# apollo3 register map
Vendor: Ambiq Micro; Series: Apollo; File version: 1.0
CPU: CM4 r1p0, little endian, MPU, FPU, 3 interrupt priority bits
Registers are 32-bit, read-write, reset 0x0 unless marked. A register's access mark holds for its fields unless they carry their own. Offsets are from the block's base; [hi:lo] are bit positions; lines under a group give offsets from that group; {n}, {i} and the like mark numbered series; 'fields as' and 'values as' point back to an identical list.

## GPIO — General Purpose IO
Base 0x40010000
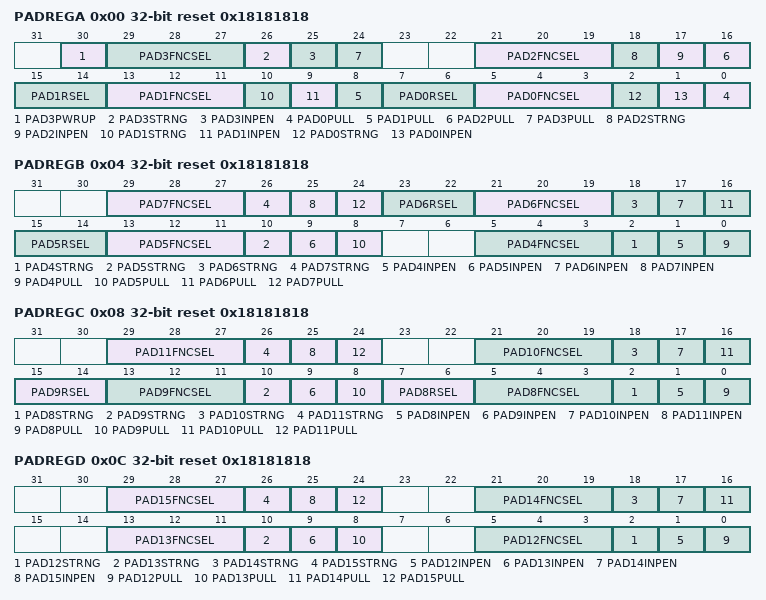
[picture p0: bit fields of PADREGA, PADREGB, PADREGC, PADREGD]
0x00 PADREGA reset 0x18181818 — Pad Configuration Register A (Pads 0-3)
  [30] PAD3PWRUP — Pad 3 VDD power switch enable
    0=DIS (Power switch disabled value.); 1=EN (Power switch enabled (switched to VDD) value.)
  [29:27] PAD3FNCSEL — Pad 3 function select
    0=UA0RTS (Configure as the UART0 RTS output value.); 1=SLnCE (Configure as the IOSLAVE SPI nCE signal value.); 2=NCE3 (IOM/MSPI nCE group 3 value.); 3=GPIO3 (Configure as GPIO3 value.); 5=MSPI7 (MSPI data connection 7 value.); 6=TRIG1 (Configure as the ADC Trigger 1 signal value.); 7=I2S_WCLK (Configure as the PDM I2S Word Clock input value.)
  [26] PAD3STRNG — Pad 3 drive strength.
    0=LOW (Low drive strength value.); 1=HIGH (High drive strength value.)
  [25] PAD3INPEN — Pad 3 input enable.
    0=DIS (Pad input disabled value.); 1=EN (Pad input enabled value.)
  [8n] PAD{n}PULL (n=0..3) — Pad {n} pullup enable
    0=DIS (Pullup disabled value.); 1=EN (Pullup enabled value.)
  [21:19] PAD2FNCSEL — Pad 2 function select
    1=SLMISO (Configure as the IOSLAVE SPI MISO signal value.); 2=UART0RX (Configure as the UART0 RX input value.); 3=GPIO2 (Configure as GPIO2 value.); 5=MSPI6 (CMSPI data connection 6 value.); 7=NCE2 (IOM/MSPI nCE group 2 value.)
  [18] PAD2STRNG — Pad 2 drive strength
    values as PAD3STRNG
  [17] PAD2INPEN — Pad 2 input enable
    values as PAD3INPEN
  [15:14] PAD1RSEL — Pad 1 pullup resistor selection.
    0=PULL1_5K (Pullup is ~1.5 KOhms value.); 1=PULL6K (Pullup is ~6 KOhms value.); 2=PULL12K (Pullup is ~12 KOhms value.); 3=PULL24K (Pullup is ~24 KOhms value.)
  [13:11] PAD1FNCSEL — Pad 1 function select
    0=SLSDAWIR3 (Configure as the IOSLAVE I2C SDA or SPI WIR3 signal value.); 1=SLMOSI (Configure as the IOSLAVE SPI MOSI signal value.); 2=UART0TX (Configure as the UART0 TX output signal value.); 3=GPIO1 (Configure as GPIO1 value.); 5=MSPI5 (MSPI data connection 5 value.); 7=NCE1 (IOM/MSPI nCE group 1 value.)
  [10] PAD1STRNG — Pad 1 drive strength
    values as PAD3STRNG
  [9] PAD1INPEN — Pad 1 input enable
    values as PAD3INPEN
  [7:6] PAD0RSEL — Pad 0 pullup resistor selection.
    values as PAD1RSEL
  [5:3] PAD0FNCSEL — Pad 0 function select
    0=SLSCL (Configure as the IOSLAVE I2C SCL signal value.); 1=SLSCK (Configure as the IOSLAVE SPI SCK signal value.); 2=CLKOUT (Configure as the CLKOUT signal value.); 3=GPIO0 (Configure as GPIO0 value.); 5=MSPI4 (MSPI data connection 4 value.); 7=NCE0 (IOM/MSPI nCE group 0 value.)
  [2] PAD0STRNG — Pad 0 drive strength
    values as PAD3STRNG
  [1] PAD0INPEN — Pad 0 input enable
    values as PAD3INPEN
0x04 PADREGB reset 0x18181818 — Pad Configuration Register B (Pads 4-7)
  [29:27] PAD7FNCSEL — Pad 7 function select
    0=NCE7 (IOM/MSPI nCE group 7 value.); 1=M0MOSI (Configure as the IOMSTR0 SPI MOSI signal value.); 2=CLKOUT (Configure as the CLKOUT signal value.); 3=GPIO7 (Configure as GPIO7 value.); 4=TRIG0 (Configure as the ADC Trigger 0 signal value.); 5=UART0TX (Configure as the UART0 TX output signal value.); 7=CT19 (CTIMER connection 19 value.)
  [8n-30] PAD{n}STRNG (n=4..7) — Pad {n} drive strength
    values as PADREGA.PAD3STRNG
  [8n-31] PAD{n}INPEN (n=4..7) — Pad {n} input enable
    values as PADREGA.PAD3INPEN
  [8n-32] PAD{n}PULL (n=4..7) — Pad {n} pullup enable
    0=DIS (Pullup disabled value.); 1=EN (Pullup enabled value.)
  [23:22] PAD6RSEL — Pad 6 pullup resistor selection.
    values as PADREGA.PAD1RSEL
  [21:19] PAD6FNCSEL — Pad 6 function select
    0=M0SDAWIR3 (Configure as the IOMSTR0 I2C SDA or SPI WIR3 signal value.); 1=M0MISO (Configure as the IOMSTR0 SPI MISO signal value.); 2=UA0CTS (Configure as the UART0 CTS input signal value.); 3=GPIO6 (Configure as GPIO6 value.); 5=CT10 (CTIMER connection 10 value.); 7=I2S_DAT (Configure as the PDM I2S Data output signal value.)
  [15:14] PAD5RSEL — Pad 5 pullup resistor selection.
    values as PADREGA.PAD1RSEL
  [13:11] PAD5FNCSEL — Pad 5 function select
    0=M0SCL (Configure as the IOMSTR0 I2C SCL signal value.); 1=M0SCK (Configure as the IOMSTR0 SPI SCK signal value.); 2=UA0RTS (Configure as the UART0 RTS signal output value.); 3=GPIO5 (Configure as GPIO5 value.); 5=EXTHFA (Configure as the External HFA input clock value.); 7=CT8 (CTIMER connection 8 value.)
  [5:3] PAD4FNCSEL — Pad 4 function select
    0=UA0CTS (Configure as the UART0 CTS input signal value.); 1=SLINT (Configure as the IOSLAVE interrupt out signal value.); 2=NCE4 (IOM/SPI nCE group 4 value.); 3=GPIO4 (Configure as GPIO4 value.); 5=UART0RX (Configure as the UART0 RX input value.); 6=CT17 (CTIMER connection 17 value.); 7=MSPI2 (MSPI data connection 2 value.)
0x08 PADREGC reset 0x18181818 — Pad Configuration Register C (Pads 8-11)
  [29:27] PAD11FNCSEL — Pad 11 function select
    0=ADCSE2 (Configure as the analog input for ADC single ended input 2 value.); 1=NCE11 (IOM/MSPI nCE group 11 value.); 2=CT31 (CTIMER connection 31 value.); 3=GPIO11 (Configure as GPIO11 value.); 4=SLINT (Configure as the IOSLAVE interrupt out signal value.); 5=UA1CTS (Configure as the UART1 CTS input signal value.); 6=UART0RX (Configure as the UART0 RX input signal value.); 7=PDM_DATA (Configure as the PDM Data input signal value.)
  [8n-62] PAD{n}STRNG (n=8..11) — Pad {n} drive strength
    values as PADREGA.PAD3STRNG
  [8n-63] PAD{n}INPEN (n=8..11) — Pad {n} input enable
    values as PADREGA.PAD3INPEN
  [8n-64] PAD{n}PULL (n=8..11) — Pad {n} pullup enable
    0=DIS (Pullup disabled value.); 1=EN (Pullup enabled value.)
  [21:19] PAD10FNCSEL — Pad 10 function select
    1=M1MOSI (Configure as the IOMSTR1 SPI MOSI signal value.); 2=NCE10 (IOM/MSPI nCE group 10 value.); 3=GPIO10 (Configure as GPIO10 value.); 4=PDMCLK (PDM serial clock out value.); 5=UA1RTS (Configure as the UART1 RTS output signal value.)
  [15:14] PAD9RSEL — Pad 9 pullup resistor selection
    values as PADREGA.PAD1RSEL
  [13:11] PAD9FNCSEL — Pad 9 function select
    0=M1SDAWIR3 (Configure as the IOMSTR1 I2C SDA or SPI WIR3 signal value.); 1=M1MISO (Configure as the IOMSTR1 SPI MISO signal value.); 2=NCE9 (IOM/MSPI nCE group 9 value.); 3=GPIO9 (Configure as GPIO9 value.); 4=SCCIO (SCARD data I/O connection value.); 6=UART1RX (Configure as UART1 RX input signal value.)
  [7:6] PAD8RSEL — Pad 8 pullup resistor selection.
    values as PADREGA.PAD1RSEL
  [5:3] PAD8FNCSEL — Pad 8 function select
    0=M1SCL (Configure as the IOMSTR1 I2C SCL signal value.); 1=M1SCK (Configure as the IOMSTR1 SPI SCK signal value.); 2=NCE8 (IOM/MSPI nCE group 8 value.); 3=GPIO8 (Configure as GPIO8 value.); 4=SCCLK (SCARD serial clock output value.); 6=UART1TX (Configure as the UART1 TX output signal value.)
0x0C PADREGD reset 0x18181818 — Pad Configuration Register D (Pads 12-15)
  [29:27] PAD15FNCSEL — Pad 15 function select
    0=ADCD1N (Configure as the analog ADC differential pair 1 N input signal value.); 1=NCE15 (IOM/MSPI nCE group 15 value.); 2=UART1RX (Configure as the UART1 RX signal value.); 3=GPIO15 (Configure as GPIO15 value.); 4=PDMDATA (PDM serial data input value.); 5=EXTXT (Configure as the external XTAL oscillator input value.); 6=SWDIO (Configure as an alternate port for the SWDIO I/O signal value.); 7=SWO (Configure as an SWO (Serial Wire Trace output) value.)
  [8n-94] PAD{n}STRNG (n=12..15) — Pad {n} drive strength
    values as PADREGA.PAD3STRNG
  [8n-95] PAD{n}INPEN (n=12..15) — Pad {n} input enable
    values as PADREGA.PAD3INPEN
  [8n-96] PAD{n}PULL (n=12..15) — Pad {n} pullup enable
    0=DIS (Pullup disabled value.); 1=EN (Pullup enabled value.)
  [21:19] PAD14FNCSEL — Pad 14 function select
    0=ADCD1P (Configure as the analog ADC differential pair 1 P input signal value.); 1=NCE14 (IOM/MSPI nCE group 14 value.); 2=UART1TX (Configure as the UART1 TX output signal value.); 3=GPIO14 (Configure as GPIO14 value.); 4=PDMCLK (PDM serial clock output value.); 5=EXTHFS (Configure as the External HFRC oscillator input select value.); 6=SWDCK (Configure as the alternate input for the SWDCK input signal value.); 7=32kHzXT (Configure as the 32kHz crystal output signal value.)
  [13:11] PAD13FNCSEL — Pad 13 function select
    0=ADCD0PSE8 (Configure as the ADC Differential pair 0 P, or Single Ended input 8 analog input signal. Determination of the D0P vs SE8 usage is done when the particular channel is selected within the ADC module value.); 1=NCE13 (IOM/MSPI nCE group 13 value.); 2=CT2 (CTIMER connection 2 value.); 3=GPIO13 (Configure as GPIO13 value.); 4=I2SBCLK (I2C interface bit clock value.); 5=EXTHFB (Configure as the external HFRC oscillator input value.); 6=UA0RTS (Configure as the UART0 RTS signal output value.); 7=UART1RX (Configure as the UART1 RX input signal value.)
  [5:3] PAD12FNCSEL — Pad 12 function select
    0=ADCD0NSE9 (Configure as the ADC Differential pair 0 N, or Single Ended input 9 analog input signal. Determination of the D0N vs SE9 usage is done when the particular channel is selected within the ADC module value.); 1=NCE12 (IOM/MSPI nCE group 12 value.); 2=CT0 (CTIMER connection 0 value.); 3=GPIO12 (Configure as GPIO12 value.); 4=SLnCE (Configure as the IOSLAVE SPI nCE signal value.); 5=PDMCLK (PDM serial clock output value.); 6=UA0CTS (Configure as the UART0 CTS input signal value.); 7=UART1TX (Configure as the UART1 TX output signal value.)
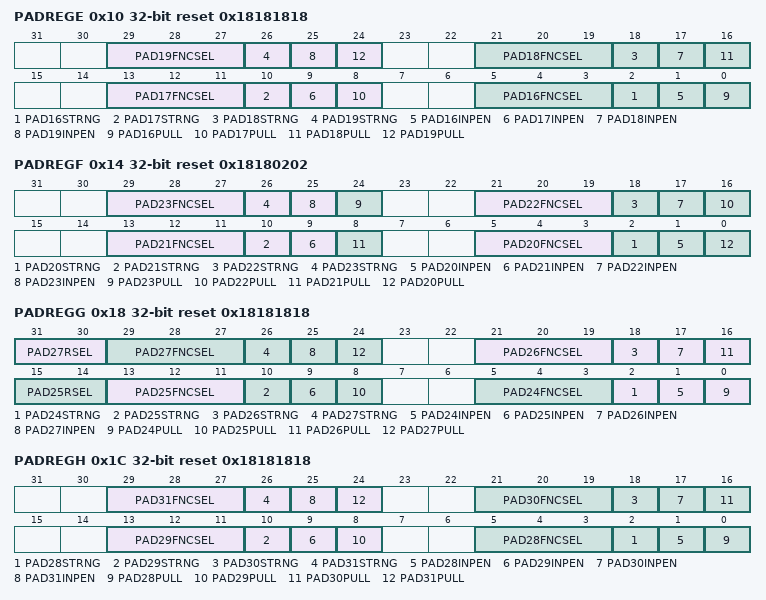
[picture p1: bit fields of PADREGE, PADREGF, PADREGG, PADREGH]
0x10 PADREGE reset 0x18181818 — Pad Configuration Register E (Pads 16-19)
  [29:27] PAD19FNCSEL — Pad 19 function select
    0=CMPRF0 (Configure as the analog comparator reference 0 signal value.); 1=NCE19 (IOM/MSPI nCE group 19 value.); 2=CT6 (CTIMER conenction 6 value.); 3=GPIO19 (Configure as GPIO19 value.); 4=SCCLK (SCARD serial clock value.); 5=ANATEST1 (Configure as the ANATEST1 I/O signal value.); 6=UART1RX (Configure as the UART1 RX input signal value.); 7=I2SBCLK (Configure as the PDM I2S bit clock input signal value.)
  [8n-126] PAD{n}STRNG (n=16..19) — Pad {n} drive strength
    values as PADREGA.PAD3STRNG
  [8n-127] PAD{n}INPEN (n=16..19) — Pad {n} input enable
    values as PADREGA.PAD3INPEN
  [8n-128] PAD{n}PULL (n=16..19) — Pad {n} pullup enable
    0=DIS (Pullup disabled value.); 1=EN (Pullup enabled value.)
  [21:19] PAD18FNCSEL — Pad 18 function select
    0=CMPIN1 (Configure as the analog comparator input 1 signal value.); 1=NCE18 (IOM/MSPI nCE group 18 value.); 2=CT4 (CTIMER connection 4 value.); 3=GPIO18 (Configure as GPIO18 value.); 4=UA0RTS (Configure as UART0 RTS output signal value.); 5=ANATEST2 (Configure as ANATEST2 I/O signal value.); 6=UART1TX (Configure as UART1 TX output signal value.); 7=SCCIO (SCARD data input/output connectin value.)
  [13:11] PAD17FNCSEL — Pad 17 function select
    0=CMPRF1 (Configure as the analog comparator reference signal 1 input signal value.); 1=NCE17 (IOM/MSPI nCE group 17 value.); 2=TRIG1 (Configure as the ADC Trigger 1 signal value.); 3=GPIO17 (Configure as GPIO17 value.); 4=SCCCLK (SCARD serial clock output value.); 6=UART0RX (Configure as UART0 RX input signal value.); 7=UA1CTS (Configure as UART1 CTS input signal value.)
  [5:3] PAD16FNCSEL — Pad 16 function select
    0=ADCSE0 (Configure as the analog ADC single ended port 0 input signal value.); 1=NCE16 (IOM/MSPI nCE group 16 value.); 2=TRIG0 (Configure as the ADC Trigger 0 signal value.); 3=GPIO16 (Configure as GPIO16 value.); 4=SCCRST (SCARD reset output value.); 5=CMPIN0 (Configure as comparator input 0 signal value.); 6=UART0TX (Configure as UART0 TX output signal value.); 7=UA1RTS (Configure as UART1 RTS output signal value.)
0x14 PADREGF reset 0x18180202 — Pad Configuration Register F (Pads 20-23)
  [29:27] PAD23FNCSEL — Pad 23 function select
    0=UART0RX (Configure as the UART0 RX signal value.); 1=NCE23 (IOM/MSPI nCE group 23 value.); 2=CT14 (CTIMER connection 14 value.); 3=GPIO23 (Configure as GPIO23 value.); 4=I2SWCLK (I2S word clock input value.); 5=CMPOUT (Configure as voltage comparitor output value.); 6=MSPI3 (MSPI data connection 3 value.); 7=EXTXT (External XTAL osacillatgor input value.)
  [8n-158] PAD{n}STRNG (n=20..23) — Pad {n} drive strength
    values as PADREGA.PAD3STRNG
  [8n-159] PAD{n}INPEN (n=20..23) — Pad {n} input enable
    values as PADREGA.PAD3INPEN
  [24] PAD23PULL — Pad 23 pullup enable
    0=DIS (Pullup disabled value.); 1=EN (Pullup enabled value.)
  [21:19] PAD22FNCSEL — Pad 22 function select
    0=UART0TX (Configure as the UART0 TX signal value.); 1=NCE22 (IOM/MSPI nCE group 22 value.); 2=CT12 (CTIMER connection 12 value.); 3=GPIO22 (Configure as GPIO22 value.); 4=PDM_CLK (Configure as the PDM CLK output value.); 5=EXTLF (External LFRC input value.); 6=MSPI0 (MSPI data connection 0 value.); 7=SWO (Configure as the serial trace data output signal value.)
  [16] PAD22PULL — Pad 22 pullup enable
    0=DIS (Pullup disabled value.); 1=EN (Pullup enabled value.)
  [13:11] PAD21FNCSEL — Pad 21 function select
    0=SWDIO (Configure as the serial wire debug data signal value.); 1=NCE21 (IOM/MSPI nCE group 21 value.); 3=GPIO21 (Configure as GPIO21 value.); 4=UART0RX (Configure as UART0 RX input signal value.); 5=UART1RX (Configure as UART1 RX input signal value.); 6=I2SBCLK (I2S byte clock input value.); 7=UA1CTS (Configure as UART1 CTS input signal value.)
  [8] PAD21PULL — Pad 21 pullup enable
    0=DIS (Pullup disabled value.); 1=EN (Pullup enabled value.)
  [5:3] PAD20FNCSEL — Pad 20 function select
    0=SWDCK (Configure as the serial wire debug clock signal value.); 1=NCE20 (IOM/MSPI nCE group 20 value.); 3=GPIO20 (Configure as GPIO20 value.); 4=UART0TX (Configure as UART0 TX output signal value.); 5=UART1TX (Configure as UART1 TX output signal value.); 6=I2SBCLK (I2S byte clock input value.); 7=UA1RTS (Configure as UART1 RTS output signal value.)
  [0] PAD20PULL — Pad 20 pulldown enable
    0=DIS (Pulldown disabled value.); 1=EN (Pulldown enabled value.)
0x18 PADREGG reset 0x18181818 — Pad Configuration Register G (Pads 24-27)
  [31:30] PAD27RSEL — Pad 27 pullup resistor selection.
    values as PADREGA.PAD1RSEL
  [29:27] PAD27FNCSEL — Pad 27 function select
    0=UART0RX (Configure as UART0 RX input signal value.); 1=NCE27 (IOM/MSPI nCE group 27 value.); 2=CT5 (CTIMER connection 5 value.); 3=GPIO27 (Configure as GPIO27 value.); 4=M2SCL (Configure as I2C clock I/O signal from IOMSTR2 value.); 5=M2SCK (Configure as SPI clock output signal from IOMSTR2 value.)
  [8n-190] PAD{n}STRNG (n=24..27) — Pad {n} drive strength
    values as PADREGA.PAD3STRNG
  [8n-191] PAD{n}INPEN (n=24..27) — Pad {n} input enable
    values as PADREGA.PAD3INPEN
  [8n-192] PAD{n}PULL (n=24..27) — Pad {n} pullup enable
    0=DIS (Pullup disabled value.); 1=EN (Pullup enabled value.)
  [21:19] PAD26FNCSEL — Pad 26 function select
    0=EXTHF (Configure as the external HFRC oscillator input value.); 1=NCE26 (IOM/MSPI nCE group 26 value.); 2=CT3 (CTIMER connection 3 value.); 3=GPIO26 (Configure as GPIO26 value.); 4=SCCRST (SCARD reset output value.); 5=MSPI1 (MSPI data connection 1 value.); 6=UART0TX (Configure as UART0 TX output signal value.); 7=UA1CTS (Configure as UART1 CTS input signal value.)
  [15:14] PAD25RSEL — Pad 25 pullup resistor selection.
    values as PADREGA.PAD1RSEL
  [13:11] PAD25FNCSEL — Pad 25 function select
    0=UART1RX (Configure as UART1 RX input signal value.); 1=NCE25 (IOM/MSPI nCE group 25 value.); 2=CT1 (CTIMER connection 1 value.); 3=GPIO25 (Configure as GPIO25 value.); 4=M2SDAWIR3 (Configure as the IOMSTR2 I2C SDA or SPI WIR3 signal value.); 5=M2MISO (Configure as the IOMSTR2 SPI MISO input signal value.)
  [5:3] PAD24FNCSEL — Pad 24 function select
    0=UART1TX (Configure as UART1 TX output signal value.); 1=NCE24 (IOM/MSPI nCE group 24 value.); 2=MSPI8 (MSPI data connection 8 value.); 3=GPIO24 (Configure as GPIO24 value.); 4=UA0CTS (Configure as UART0 CTS input signal value.); 5=CT21 (CTIMER connection 21 value.); 6=32kHzXT (Configure as the 32kHz crystal output signal value.); 7=SWO (Configure as the serial trace data output signal value.)
0x1C PADREGH reset 0x18181818 — Pad Configuration Register H (Pads 28-31)
  [29:27] PAD31FNCSEL — Pad 31 function select
    0=ADCSE3 (Configure as the analog input for ADC single ended input 3 value.); 1=NCE31 (IOM/MSPI nCE group 31 value.); 2=CT13 (CTIMER connection 13 value.); 3=GPIO31 (Configure as GPIO31 value.); 4=UART0RX (Configure as the UART0 RX input signal value.); 5=SCCCLK (SCARD serial clock output value.); 7=UA1RTS (Configure as UART1 RTS output signal value.)
  [8n-222] PAD{n}STRNG (n=28..31) — Pad {n} drive strength
    values as PADREGA.PAD3STRNG
  [8n-223] PAD{n}INPEN (n=28..31) — Pad {n} input enable
    values as PADREGA.PAD3INPEN
  [8n-224] PAD{n}PULL (n=28..31) — Pad {n} pullup enable
    0=DIS (Pullup disabled value.); 1=EN (Pullup enabled value.)
  [21:19] PAD30FNCSEL — Pad 30 function select
    0=ANATEST1 (Configure as the ANATEST1 I/O signal value.); 1=NCE30 (IOM/MSPI nCE group 30 value.); 2=CT11 (CTIMER connection 11 value.); 3=GPIO30 (Configure as GPIO30 value.); 4=UART0TX (Configure as UART0 TX output signal value.); 5=UA1RTS (Configure as UART1 RTS output signal value.); 7=I2S_DAT (Configure as the PDM I2S Data output signal value.)
  [13:11] PAD29FNCSEL — Pad 29 function select
    0=ADCSE1 (Configure as the analog input for ADC single ended input 1 value.); 1=NCE29 (IOM/MSPI nCE group 29 value.); 2=CT9 (CTIMER connection 9 value.); 3=GPIO29 (Configure as GPIO29 value.); 4=UA0CTS (Configure as the UART0 CTS input signal value.); 5=UA1CTS (Configure as the UART1 CTS input signal value.); 6=UART0RX (Configure as the UART0 RX input signal value.); 7=PDM_DATA (Configure as PDM DATA input value.)
  [5:3] PAD28FNCSEL — Pad 28 function select
    0=I2S_WCLK (Configure as the PDM I2S Word Clock input value.); 1=NCE28 (IOM/MSPI nCE group 28 value.); 2=CT7 (CTIMER connection 7 value.); 3=GPIO28 (Configure as GPIO28 value.); 5=M2MOSI (Configure as the IOMSTR2 SPI MOSI output signal value.); 6=UART0TX (Configure as the UART0 TX output signal value.)
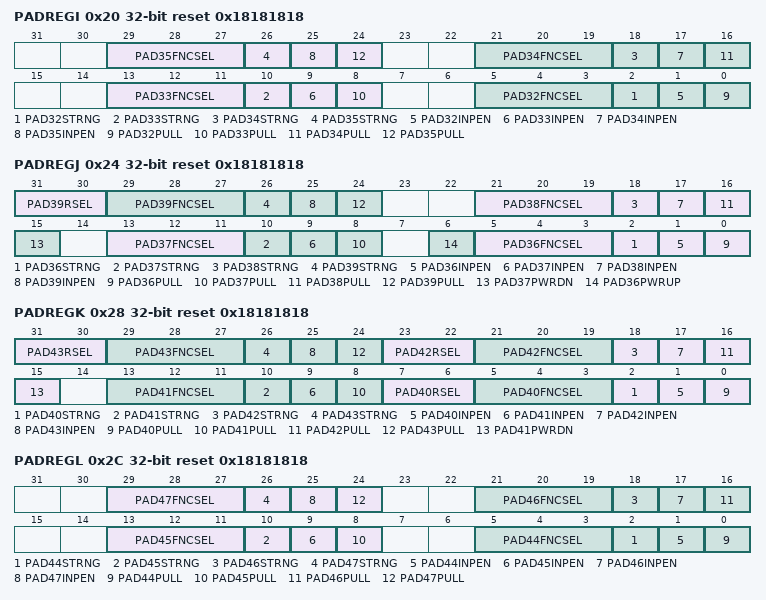
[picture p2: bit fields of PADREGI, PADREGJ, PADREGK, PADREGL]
0x20 PADREGI reset 0x18181818 — Pad Configuration Register I (Pads 32-25)
  [29:27] PAD35FNCSEL — Pad 35 function select
    0=ADCSE7 (Configure as the analog input for ADC single ended input 7 value.); 1=NCE35 (IOM/MSPI nCE group 35 value.); 2=UART1TX (Configure as the UART1 TX signal value.); 3=GPIO35 (Configure as GPIO35 value.); 4=I2SDAT (I2S serial data output value.); 5=CT27 (CTIMER connection 27 value.); 6=UA0RTS (Configure as the UART0 RTS output value.)
  [8n-254] PAD{n}STRNG (n=32..35) — Pad {n} drive strength
    values as PADREGA.PAD3STRNG
  [8n-255] PAD{n}INPEN (n=32..35) — Pad {n} input enable
    values as PADREGA.PAD3INPEN
  [8n-256] PAD{n}PULL (n=32..35) — Pad {n} pullup enable
    0=DIS (Pullup disabled value.); 1=EN (Pullup enabled value.)
  [21:19] PAD34FNCSEL — Pad 34 function select
    0=ADCSE6 (Configure as the analog input for ADC single ended input 6 value.); 1=NCE34 (IOM/MSPI nCE group 34 value.); 2=UA1RTS (Configure as the UART1 RTS output value.); 3=GPIO34 (Configure as GPIO34 value.); 4=CMPRF2 (Configure as the analog comparator reference 2 signal value.); 5=UA0RTS (Configure as the UART0 RTS output value.); 6=UART0RX (Configure as the UART0 RX input value.); 7=PDMDATA (PDM serial data input value.)
  [13:11] PAD33FNCSEL — Pad 33 function select
    0=ADCSE5 (Configure as the analog ADC single ended port 5 input signal value.); 1=NCE33 (IOM/MSPI nCE group 33 value.); 2=32kHzXT (Configure as the 32kHz crystal output signal value.); 3=GPIO33 (Configure as GPIO33 value.); 5=UA0CTS (Configure as the UART0 CTS input value.); 6=CT23 (CTIMER connection 23 value.); 7=SWO (Configure as the serial trace data output signal value.)
  [5:3] PAD32FNCSEL — Pad 32 function select
    0=ADCSE4 (Configure as the analog input for ADC single ended input 4 value.); 1=NCE32 (IOM/MSPI nCE group 32 value.); 2=CT15 (CTIMER connection 15 value.); 3=GPIO32 (Configure as GPIO32 value.); 4=SCCIO (SCARD serial data input/output value.); 5=EXTLF (External input to the LFRC oscillator value.); 7=UA1CTS (Configure as the UART1 CTS input value.)
0x24 PADREGJ reset 0x18181818 — Pad Configuration Register J (Pads 36-39)
  [31:30] PAD39RSEL — Pad 39 pullup resistor selection.
    values as PADREGA.PAD1RSEL
  [29:27] PAD39FNCSEL — Pad 39 function select
    0=UART0TX (Configure as the UART0 TX output signal value.); 1=UART1TX (Configure as the UART1 TX output signal value.); 2=CT25 (CTIMER connection 25 value.); 3=GPIO39 (Configure as GPIO39 value.); 4=M4SCL (Configure as the IOMSTR4 I2C SCL signal value.); 5=M4SCK (Configure as the IOMSTR4 SPI SCK signal value.)
  [8n-286] PAD{n}STRNG (n=36..39) — Pad {n} drive strength
    values as PADREGA.PAD3STRNG
  [8n-287] PAD{n}INPEN (n=36..39) — Pad {n} input enable
    values as PADREGA.PAD3INPEN
  [8n-288] PAD{n}PULL (n=36..39) — Pad {n} pullup enable
    0=DIS (Pullup disabled value.); 1=EN (Pullup enabled value.)
  [21:19] PAD38FNCSEL — Pad 38 function select
    0=TRIG3 (Configure as the ADC Trigger 3 signal value.); 1=NCE38 (IOM/MSPI nCE group 38 value.); 2=UA0CTS (Configure as the UART0 CTS signal value.); 3=GPIO38 (Configure as GPIO38 value.); 5=M3MOSI (Configure as the IOMSTR3 SPI MOSI output signal value.); 6=UART1RX (Configure as the UART1 RX input signal value.)
  [15] PAD37PWRDN — Pad 37 VSS power switch enable
    0=DIS (Power switch disabled value.); 1=EN (Power switch enabled (switch to GND) value.)
  [13:11] PAD37FNCSEL — Pad 37 function select
    0=TRIG2 (Configure as the ADC Trigger 2 signal value.); 1=NCE37 (IOM/MSPI nCE group 37 value.); 2=UA0RTS (Configure as the UART0 RTS output signal value.); 3=GPIO37 (Configure as GPIO37 value.); 4=SCCIO (SCARD serial data input/output value.); 5=UART1TX (Configure as the UART1 TX output signal value.); 6=PDMCLK (Configure as the PDM CLK output signal value.); 7=CT29 (CTIMER connection 29 value.)
  [6] PAD36PWRUP — Pad 36 VDD power switch enable
    values as PADREGA.PAD3PWRUP
  [5:3] PAD36FNCSEL — Pad 36 function select
    0=TRIG1 (Configure as the ADC Trigger 1 signal value.); 1=NCE36 (IOM/MSPI nCE group 36 value.); 2=UART1RX (Configure as the UART1 RX input signal value.); 3=GPIO36 (Configure as GPIO36 value.); 4=32kHzXT (Configure as the 32kHz output clock from the crystal value.); 5=UA1CTS (Configure as the UART1 CTS input signal value.); 6=UA0CTS (Configure as the UART0 CTS input signal value.); 7=PDMDATA (PDM serial data input value.)
0x28 PADREGK reset 0x18181818 — Pad Configuration Register K (Pads 40-43)
  [31:30] PAD43RSEL — Pad 43 pullup resistor selection.
    values as PADREGA.PAD1RSEL
  [29:27] PAD43FNCSEL — Pad 43 function select
    0=UART1RX (Configure as the UART1 RX input signal value.); 1=NCE43 (IOM/MSPI nCE group 43 value.); 2=CT18 (CTIMER connection 18 value.); 3=GPIO43 (Configure as GPIO43 value.); 4=M3SDAWIR3 (Configure as the IOMSTR3 I2C SDA or SPI WIR3 signal value.); 5=M3MISO (Configure as the IOMSTR3 SPI MISO signal value.)
  [8n-318] PAD{n}STRNG (n=40..43) — Pad {n} drive strength
    values as PADREGA.PAD3STRNG
  [8n-319] PAD{n}INPEN (n=40..43) — Pad {n} input enable
    values as PADREGA.PAD3INPEN
  [8n-320] PAD{n}PULL (n=40..43) — Pad {n} pullup enable
    0=DIS (Pullup disabled value.); 1=EN (Pullup enabled value.)
  [23:22] PAD42RSEL — Pad 42 pullup resistor selection.
    values as PADREGA.PAD1RSEL
  [21:19] PAD42FNCSEL — Pad 42 function select
    0=UART1TX (Configure as the UART1 TX output signal value.); 1=NCE42 (IOM/MSPI nCE group 42 value.); 2=CT16 (CTIMER connection 16 value.); 3=GPIO42 (Configure as GPIO42 value.); 4=M3SCL (Configure as the IOMSTR3 I2C SCL clock I/O signal value.); 5=M3SCK (Configure as the IOMSTR3 SPI SCK output value.)
  [15] PAD41PWRDN — Pad 41 power switch enable
    0=DIS (Power switch disabled value.); 1=EN (Power switch enabled (Switch pad to VSS) value.)
  [13:11] PAD41FNCSEL — Pad 41 function select
    0=NCE41 (IOM/MSPI nCE group 41 value.); 2=SWO (Configure as the serial wire debug SWO signal value.); 3=GPIO41 (Configure as GPIO41 value.); 4=I2SWCLK (I2S word clock input value.); 5=UA1RTS (Configure as the UART1 RTS output signal value.); 6=UART0TX (Configure as the UART0 TX output signal value.); 7=UA0RTS (Configure as the UART0 RTS output signal value.)
  [7:6] PAD40RSEL — Pad 40 pullup resistor selection.
    values as PADREGA.PAD1RSEL
  [5:3] PAD40FNCSEL — Pad 40 function select
    0=UART0RX (Configure as the UART0 RX input signal value.); 1=UART1RX (Configure as the UART1 RX input signal value.); 2=TRIG0 (Configure as the ADC Trigger 0 signal value.); 3=GPIO40 (Configure as GPIO40 value.); 4=M4SDAWIR3 (Configure as the IOMSTR4 I2C SDA or SPI WIR3 signal value.); 5=M4MISO (Configure as the IOMSTR4 SPI MISO input signal value.)
0x2C PADREGL reset 0x18181818 — Pad Configuration Register L (Pads 44-47)
  [29:27] PAD47FNCSEL — Pad 47 function select
    0=32kHzXT (Configure as the 32kHz output clock from the crystal value.); 1=NCE47 (IOM/MSPI nCE group 47 value.); 2=CT26 (CTIMER connection 26 value.); 3=GPIO47 (Configure as GPIO47 value.); 5=M5MOSI (Configure as the IOMSTR5 SPI MOSI output signal value.); 6=UART1RX (Configure as the UART1 RX input signal value.)
  [8n-350] PAD{n}STRNG (n=44..47) — Pad {n} drive strength
    values as PADREGA.PAD3STRNG
  [8n-351] PAD{n}INPEN (n=44..47) — Pad {n} input enable
    values as PADREGA.PAD3INPEN
  [8n-352] PAD{n}PULL (n=44..47) — Pad {n} pullup enable
    0=DIS (Pullup disabled value.); 1=EN (Pullup enabled value.)
  [21:19] PAD46FNCSEL — Pad 46 function select
    0=32khz_XT (Configure as the 32kHz output clock from the crystal value.); 1=NCE46 (IOM/MSPI nCE group 46 value.); 2=CT24 (CTIMER connection 24 value.); 3=GPIO46 (Configure as GPIO46 value.); 4=SCCRST (SCARD reset output value.); 5=PDMCLK (PDM serial clock output value.); 6=UART1TX (Configure as the UART1 TX output signal value.); 7=SWO (Configure as the serial wire debug SWO signal value.)
  [13:11] PAD45FNCSEL — Pad 45 function select
    0=UA1CTS (Configure as the UART1 CTS input signal value.); 1=NCE45 (IOM/MSPI nCE group 45 value.); 2=CT22 (CTIMER connection 22 value.); 3=GPIO45 (Configure as GPIO45 value.); 4=I2SDAT (I2S serial data output value.); 5=PDMDATA (PDM serial data input value.); 6=UART0RX (Configure as the SPI channel 5 nCE signal from IOMSTR5 value.); 7=SWO (Configure as the serial wire debug SWO signal value.)
  [5:3] PAD44FNCSEL — Pad 44 function select
    0=UA1RTS (Configure as the UART1 RTS output signal value.); 1=NCE44 (IOM/MSPI nCE group 44 value.); 2=CT20 (CTIMER connection 20 value.); 3=GPIO44 (Configure as GPIO44 value.); 5=M4MOSI (Configure as the IOMSTR4 SPI MOSI signal value.); 6=M5nCE6 (Configure as the SPI channel 6 nCE signal from IOMSTR5 value.)
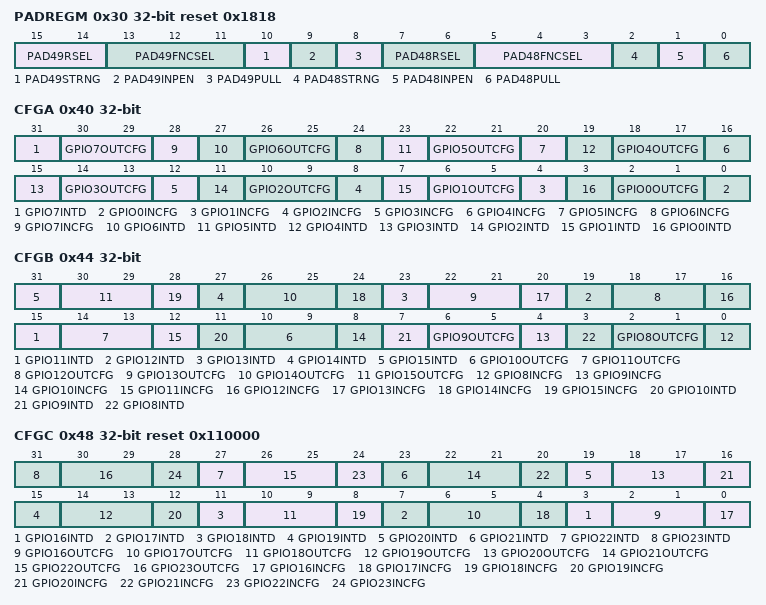
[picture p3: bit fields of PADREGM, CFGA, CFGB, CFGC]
0x30 PADREGM reset 0x1818 — Pad Configuration Register M (Pads 47-48)
  [15:14] PAD49RSEL — Pad 49 pullup resistor selection.
    values as PADREGA.PAD1RSEL
  [13:11] PAD49FNCSEL — Pad 49 function select
    0=UART0RX (Configure as the UART0 RX input signal value.); 1=NCE49 (IOM/MSPPI nCE group 49 value.); 2=CT30 (CTIMER connection 30 value.); 3=GPIO49 (Configure as GPIO49 value.); 4=M5SDAWIR3 (Configure as the IOMSTR5 I2C SDA or SPI WIR3 signal value.); 5=M5MISO (Configure as the IOMSTR5 SPI MISO input signal value.)
  [10] PAD49STRNG — Pad 49 drive strength
    values as PADREGA.PAD3STRNG
  [9] PAD49INPEN — Pad 49 input enable
    values as PADREGA.PAD3INPEN
  [8] PAD49PULL — Pad 49 pullup enable
    0=DIS (Pullup disabled value.); 1=EN (Pullup enabled value.)
  [7:6] PAD48RSEL — Pad 48 pullup resistor selection.
    values as PADREGA.PAD1RSEL
  [5:3] PAD48FNCSEL — Pad 48 function select
    0=UART0TX (Configure as the UART0 TX output signal value.); 1=NCE48 (IOM/MSPI nCE group 48 value.); 2=CT28 (CTIMER conenction 28 value.); 3=GPIO48 (Configure as GPIO48 value.); 4=M5SCL (Configure as the IOMSTR5 I2C SCL clock I/O signal value.); 5=M5SCK (Configure as the IOMSTR5 SPI SCK output value.)
  [2] PAD48STRNG — Pad 48 drive strength
    values as PADREGA.PAD3STRNG
  [1] PAD48INPEN — Pad 48 input enable
    values as PADREGA.PAD3INPEN
  [0] PAD48PULL — Pad 48 pullup enable
    0=DIS (Pullup disabled value.); 1=EN (Pullup enabled value.)
0x40 CFGA — GPIO Configuration Register A (Pads 0-7)
  [31] GPIO7INTD — GPIO7 interrupt direction, nCE polarity.
    0=nCELOW (FNCSEL = 0x0 - nCE polarity active low value.); 1=nCEHIGH (FNCSEL = 0x0 - nCE polarity active high value.)
  [4n+2:4n+1] GPIO{n}OUTCFG (n=0..7) — GPIO{n} output configuration.
    0=DIS (FNCSEL = 0x3 - Output disabled value.); 1=PUSHPULL (FNCSEL = 0x3 - Output is push-pull value.); 2=OD (FNCSEL = 0x3 - Output is open drain value.); 3=TS (FNCSEL = 0x3 - Output is tri-state value.)
  [4n] GPIO{n}INCFG (n=0..7) — GPIO{n} input enable.
    0=READ (Read the GPIO pin data value.); 1=RDZERO (INTD = 0 - Readback will always be zero value.)
  [27] GPIO6INTD — GPIO6 interrupt direction.
    0=INTDIS (INCFG = 1 - No interrupt on GPIO transition value.); 1=INTBOTH (INCFG = 1 - Interrupt on either low to high or high to low GPIO transition value.)
  [23] GPIO5INTD — GPIO5 interrupt direction.
    values as GPIO6INTD
  [19] GPIO4INTD — GPIO4 interrupt direction.
    0=nCELOW (FNCSEL = 0x2 - nCE polarity active low value.); 1=nCEHIGH (FNCSEL = 0x2 - nCE polarity active high value.)
  [15] GPIO3INTD — GPIO3 interrupt direction.
    values as GPIO4INTD
  [11] GPIO2INTD — GPIO2 interrupt direction.
    0=nCELOW (FNCSEL = 0x7 - nCE polarity active low value.); 1=nCEHIGH (FNCSEL = 0x7 - nCE polarity active high value.)
  [7] GPIO1INTD — GPIO1 interrupt direction.
    values as GPIO2INTD
  [3] GPIO0INTD — GPIO0 interrupt direction.
    values as GPIO2INTD
0x44 CFGB — GPIO Configuration Register B (Pads 8-15)
  [4n-29] GPIO{n}INTD (n=11..15) — GPIO{n} interrupt direction.
    0=nCELOW (FNCSEL = 0x1 - nCE polarity active low value.); 1=nCEHIGH (FNCSEL = 0x1 - nCE polarity active high value.)
  [4n-30:4n-31] GPIO{n}OUTCFG (n=8..15) — GPIO{n} output configuration.
    values as CFGA.GPIO0OUTCFG
  [4n-32] GPIO{n}INCFG (n=8..15) — GPIO{n} input enable.
    values as CFGA.GPIO0INCFG
  [11] GPIO10INTD — GPIO10 interrupt direction.
    values as CFGA.GPIO4INTD
  [7] GPIO9INTD — GPIO9 interrupt direction.
    values as CFGA.GPIO4INTD
  [3] GPIO8INTD — GPIO8 interrupt direction.
    values as CFGA.GPIO4INTD
0x48 CFGC reset 0x110000 — GPIO Configuration Register C (Pads 16-23)
  [4n-61] GPIO{n}INTD (n=16..23) — GPIO{n} interrupt direction.
    values as CFGB.GPIO11INTD
  [4n-62:4n-63] GPIO{n}OUTCFG (n=16..23) — GPIO{n} output configuration.
    values as CFGA.GPIO0OUTCFG
  [4n-64] GPIO{n}INCFG (n=16..23) — GPIO{n} input enable.
    values as CFGA.GPIO0INCFG
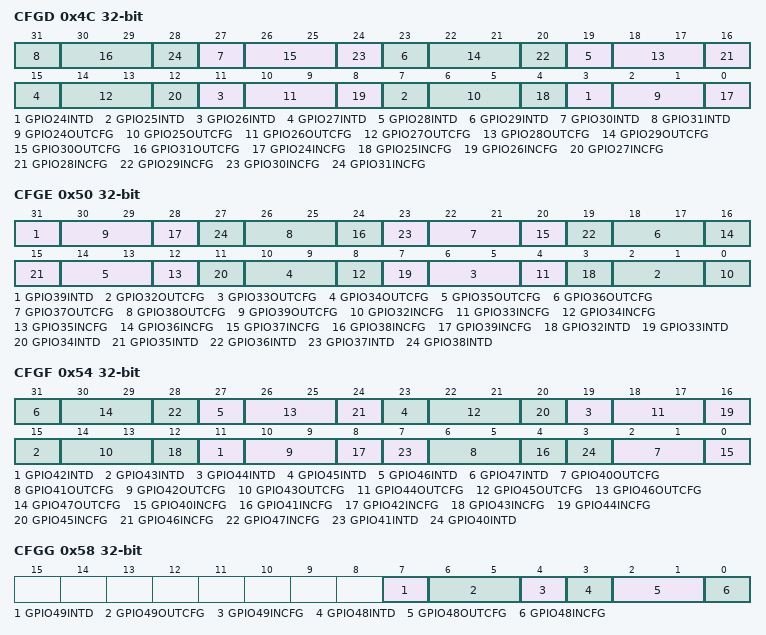
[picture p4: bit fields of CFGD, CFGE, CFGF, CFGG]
0x4C CFGD — GPIO Configuration Register D (Pads 24-31)
  [4n-93] GPIO{n}INTD (n=24..31) — GPIO{n} interrupt direction.
    values as CFGB.GPIO11INTD
  [4n-94:4n-95] GPIO{n}OUTCFG (n=24..31) — GPIO{n} output configuration.
    values as CFGA.GPIO0OUTCFG
  [4n-96] GPIO{n}INCFG (n=24..31) — GPIO{n} input enable.
    values as CFGA.GPIO0INCFG
0x50 CFGE — GPIO Configuration Register E (Pads 32-39)
  [31] GPIO39INTD — GPIO39 interrupt direction.
    values as CFGA.GPIO6INTD
  [4n-126:4n-127] GPIO{n}OUTCFG (n=32..39) — GPIO{n} output configuration.
    values as CFGA.GPIO0OUTCFG
  [4n-128] GPIO{n}INCFG (n=32..39) — GPIO{n} input enable.
    values as CFGA.GPIO0INCFG
  [4n-125] GPIO{n}INTD (n=32..38) — GPIO{n} interrupt direction.
    values as CFGB.GPIO11INTD
0x54 CFGF — GPIO Configuration Register F (Pads 40 -47)
  [4n-157] GPIO{n}INTD (n=42..47) — GPIO{n} interrupt direction.
    values as CFGB.GPIO11INTD
  [4n-158:4n-159] GPIO{n}OUTCFG (n=40..47) — GPIO{n} output configuration.
    values as CFGA.GPIO0OUTCFG
  [4n-160] GPIO{n}INCFG (n=40..47) — GPIO{n} input enable.
    values as CFGA.GPIO0INCFG
  [7] GPIO41INTD — GPIO41 interrupt direction.
    values as CFGA.GPIO7INTD
  [3] GPIO40INTD — GPIO40 interrupt direction.
    values as CFGA.GPIO6INTD
0x58 CFGG — GPIO Configuration Register G (Pads 48-49)
  [7] GPIO49INTD — GPIO49 interrupt direction.
    values as CFGB.GPIO11INTD
  [6:5] GPIO49OUTCFG — GPIO49 output configuration.
    values as CFGA.GPIO0OUTCFG
  [4] GPIO49INCFG — GPIO49 input enable.
    values as CFGA.GPIO0INCFG
  [3] GPIO48INTD — GPIO48 interrupt direction.
    values as CFGB.GPIO11INTD
  [2:1] GPIO48OUTCFG — GPIO48 output configuration.
    values as CFGA.GPIO0OUTCFG
  [0] GPIO48INCFG — GPIO48 input enable.
    values as CFGA.GPIO0INCFG
0x60 PADKEY — Key Register for all pad configuration registers
  [31:0] PADKEY — Key register value.
    115=Key (Key value.)
0x80 RDA — GPIO Input Register A
  [31:0] RDA — GPIO31-0 read data.
0x84 RDB — GPIO Input Register B
  [17:0] RDB — GPIO49-32 read data.
0x88 WTA — GPIO Output Register A
  [31:0] WTA — GPIO31-0 write data.
0x8C WTB — GPIO Output Register B
  [17:0] WTB — GPIO49-32 write data.
0x90 WTSA — GPIO Output Register A Set
  [31:0] WTSA — Set the GPIO31-0 write data.
0x94 WTSB — GPIO Output Register B Set
  [17:0] WTSB — Set the GPIO49-32 write data.
0x98 WTCA — GPIO Output Register A Clear
  [31:0] WTCA — Clear the GPIO31-0 write data.
0x9C WTCB — GPIO Output Register B Clear
  [17:0] WTCB — Clear the GPIO49-32 write data.
0xA0 ENA — GPIO Enable Register A
  [31:0] ENA — GPIO31-0 output enables
0xA4 ENB — GPIO Enable Register B
  [17:0] ENB — GPIO49-32 output enables
0xA8 ENSA — GPIO Enable Register A Set
  [31:0] ENSA — Set the GPIO31-0 output enables
0xAC ENSB — GPIO Enable Register B Set
  [17:0] ENSB — Set the GPIO49-32 output enables
0xB4 ENCA — GPIO Enable Register A Clear
  [31:0] ENCA — Clear the GPIO31-0 output enables
0xB8 ENCB — GPIO Enable Register B Clear
  [17:0] ENCB — Clear the GPIO49-32 output enables
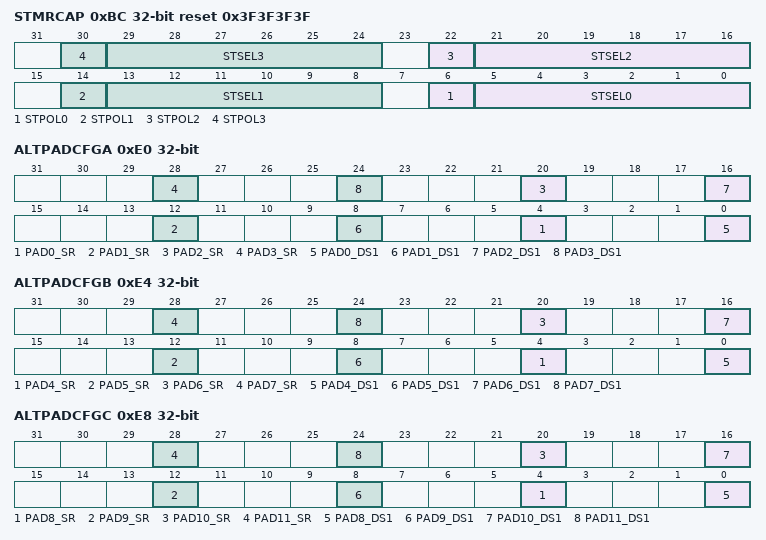
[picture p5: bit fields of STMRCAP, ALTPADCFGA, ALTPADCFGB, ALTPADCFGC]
0xBC STMRCAP reset 0x3F3F3F3F — STIMER Capture Control
  [8n+6] STPOL{n} (n=0..3) — STIMER Capture {n} Polarity.
    0=CAPLH (Capture on low to high GPIO transition value.); 1=CAPHL (Capture on high to low GPIO transition value.)
  [8n+5:8n] STSEL{n} (n=0..3) — STIMER Capture {n} Select.
{0xC0+4i} IOM{i}IRQ reset 0x3F (i=0..5) — IOM{i} Flow Control IRQ Select
  [5:0] IOM{i}IRQ — IOMSTR{i} IRQ pad select.
0xD8 BLEIFIRQ reset 0x3F — BLEIF Flow Control IRQ Select
  [5:0] BLEIFIRQ — BLEIF IRQ pad select.
0xDC GPIOOBS — GPIO Observation Mode Sample register
  [15:0] OBS_DATA — Sample of the data output on the GPIO observation port. May have async sampling issues, as the data is not synronized to the read operation. Intended for debug purposes only
0xE0 ALTPADCFGA — Alternate Pad Configuration reg0 (Pads 3,2,1,0)
  [8n+4] PAD{n}_SR (n=0..3) — Pad {n} slew rate selection.
    1=SR_EN (Enables Slew rate control on pad value.)
  [8n] PAD{n}_DS1 (n=0..3) — Pad {n} high order drive strength selection. Used in conjunction with PAD{n}STRNG field to set the pad drive strength.
0xE4 ALTPADCFGB — Alternate Pad Configuration reg1 (Pads 7,6,5,4)
  [8n-28] PAD{n}_SR (n=4..7) — Pad {n} slew rate selection.
    1=SR_EN (Enables Slew rate control on pad value.)
  [8n-32] PAD{n}_DS1 (n=4..7) — Pad {n} high order drive strength selection. Used in conjunction with PAD{n}STRNG field to set the pad drive strength.
0xE8 ALTPADCFGC — Alternate Pad Configuration reg2 (Pads 11,10,9,8)
  [8n-60] PAD{n}_SR (n=8..11) — Pad {n} slew rate selection.
    1=SR_EN (Enables Slew rate control on pad value.)
  [8n-64] PAD{n}_DS1 (n=8..11) — Pad {n} high order drive strength selection. Used in conjunction with PAD{n}STRNG field to set the pad drive strength.
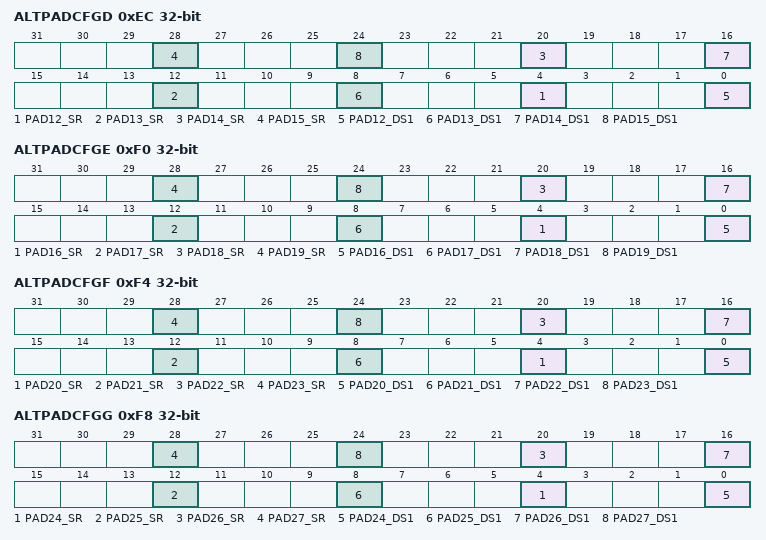
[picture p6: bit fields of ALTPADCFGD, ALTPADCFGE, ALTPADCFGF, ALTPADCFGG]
0xEC ALTPADCFGD — Alternate Pad Configuration reg3 (Pads 15,14,13,12)
  [8n-92] PAD{n}_SR (n=12..15) — Pad {n} slew rate selection.
    1=SR_EN (Enables Slew rate control on pad value.)
  [8n-96] PAD{n}_DS1 (n=12..15) — Pad {n} high order drive strength selection. Used in conjunction with PAD{n}STRNG field to set the pad drive strength.
0xF0 ALTPADCFGE — Alternate Pad Configuration reg4 (Pads 19,18,17,16)
  [8n-124] PAD{n}_SR (n=16..19) — Pad {n} slew rate selection.
    1=SR_EN (Enables Slew rate control on pad value.)
  [8n-128] PAD{n}_DS1 (n=16..19) — Pad {n} high order drive strength selection. Used in conjunction with PAD{n}STRNG field to set the pad drive strength.
0xF4 ALTPADCFGF — Alternate Pad Configuration reg5 (Pads 23,22,21,20)
  [8n-156] PAD{n}_SR (n=20..23) — Pad {n} slew rate selection.
    1=SR_EN (Enables Slew rate control on pad value.)
  [8n-160] PAD{n}_DS1 (n=20..23) — Pad {n} high order drive strength selection. Used in conjunction with PAD{n}STRNG field to set the pad drive strength.
0xF8 ALTPADCFGG — Alternate Pad Configuration reg6 (Pads 27,26,25,24)
  [8n-188] PAD{n}_SR (n=24..27) — Pad {n} slew rate selection.
    1=SR_EN (Enables Slew rate control on pad value.)
  [8n-192] PAD{n}_DS1 (n=24..27) — Pad {n} high order drive strength selection. Used in conjunction with PAD{n}STRNG field to set the pad drive strength.
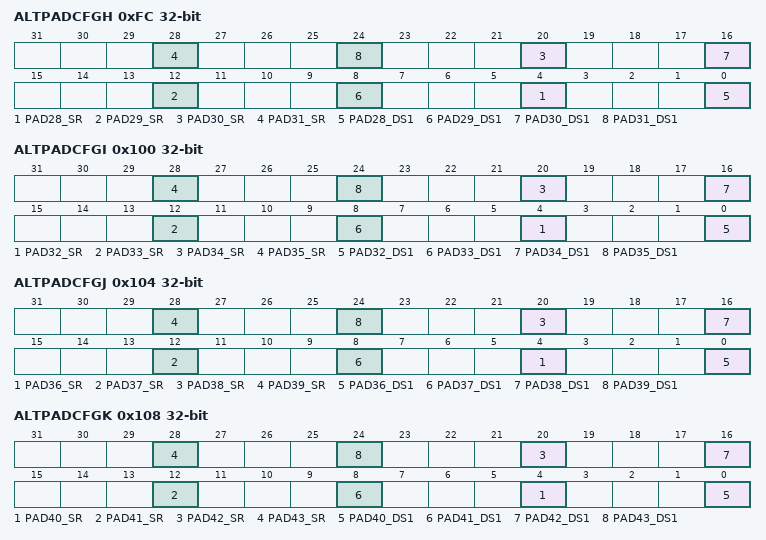
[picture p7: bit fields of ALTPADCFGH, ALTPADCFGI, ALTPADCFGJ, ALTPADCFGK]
0xFC ALTPADCFGH — Alternate Pad Configuration reg7 (Pads 31,30,29,28)
  [8n-220] PAD{n}_SR (n=28..31) — Pad {n} slew rate selection.
    1=SR_EN (Enables Slew rate control on pad value.)
  [8n-224] PAD{n}_DS1 (n=28..31) — Pad {n} high order drive strength selection. Used in conjunction with PAD{n}STRNG field to set the pad drive strength.
0x100 ALTPADCFGI — Alternate Pad Configuration reg8 (Pads 35,34,33,32)
  [8n-252] PAD{n}_SR (n=32..35) — Pad {n} slew rate selection.
    1=SR_EN (Enables Slew rate control on pad value.)
  [8n-256] PAD{n}_DS1 (n=32..35) — Pad {n} high order drive strength selection. Used in conjunction with PAD{n}STRNG field to set the pad drive strength.
0x104 ALTPADCFGJ — Alternate Pad Configuration reg9 (Pads 39,38,37,36)
  [8n-284] PAD{n}_SR (n=36..39) — Pad {n} slew rate selection.
    1=SR_EN (Enables Slew rate control on pad value.)
  [8n-288] PAD{n}_DS1 (n=36..39) — Pad {n} high order drive strength selection. Used in conjunction with PAD{n}STRNG field to set the pad drive strength.
0x108 ALTPADCFGK — Alternate Pad Configuration reg10 (Pads 43,42,41,40)
  [8n-316] PAD{n}_SR (n=40..43) — Pad {n} slew rate selection.
    1=SR_EN (Enables Slew rate control on pad value.)
  [8n-320] PAD{n}_DS1 (n=40..43) — Pad {n} high order drive strength selection. Used in conjunction with PAD{n}STRNG field to set the pad drive strength.
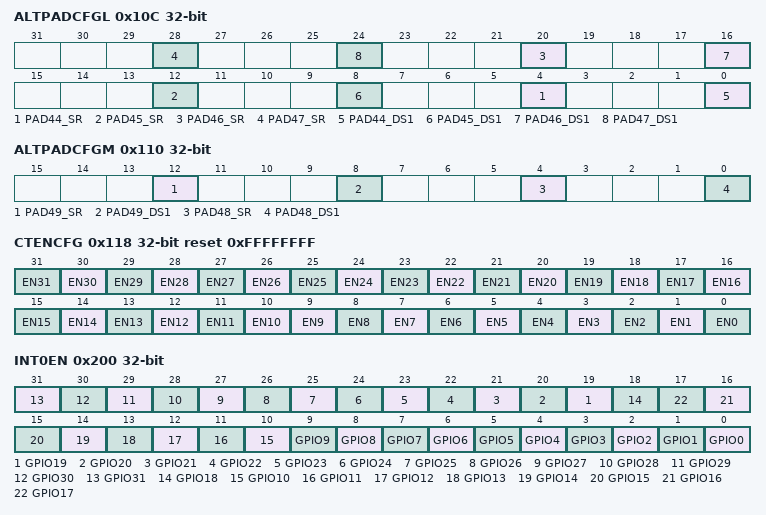
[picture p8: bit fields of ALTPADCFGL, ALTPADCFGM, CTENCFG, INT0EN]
0x10C ALTPADCFGL — Alternate Pad Configuration reg11 (Pads 47,46,45,44)
  [8n-348] PAD{n}_SR (n=44..47) — Pad {n} slew rate selection.
    1=SR_EN (Enables Slew rate control on pad value.)
  [8n-352] PAD{n}_DS1 (n=44..47) — Pad {n} high order drive strength selection. Used in conjunction with PAD{n}STRNG field to set the pad drive strength.
0x110 ALTPADCFGM — Alternate Pad Configuration reg12 (Pads 49,48)
  [12] PAD49_SR — Pad 49 slew rate selection.
    1=SR_EN (Enables Slew rate control on pad value.)
  [8] PAD49_DS1 — Pad 49 high order drive strength selection. Used in conjunction with PAD49STRNG field to set the pad drive strength.
  [4] PAD48_SR — Pad 48 slew rate selection.
    1=SR_EN (Enables Slew rate control on pad value.)
  [0] PAD48_DS1 — Pad 48 high order drive strength selection. Used in conjunction with PAD48STRNG field to set the pad drive strength.
0x114 SCDET reset 0x3F — SCARD Card Detect select
  [5:0] SCDET — SCARD card detect pad select.
0x118 CTENCFG reset 0xFFFFFFFF — Counter/Timer Enable Config
  [n] EN{n} (n=10..31) — CT{n} Enable
    1=DIS (Disable CT{n} for output value.); 0=EN (Enable CT{n} for output value.)
  [9] EN9 — CT9 Enable
    0=DIS (Disable CT9 for output value.)
  [n] EN{n} (n=0..8) — CT{n} Enable
    values as EN10
0x200 INT0EN — GPIO Interrupt Registers 31-0: Enable
  [n] GPIO{n} (n=19..31) — GPIO{n} interrupt.
  [18] GPIO18 — GPIO18interrupt.
  [n] GPIO{n} (n=0..17) — GPIO{n} interrupt.
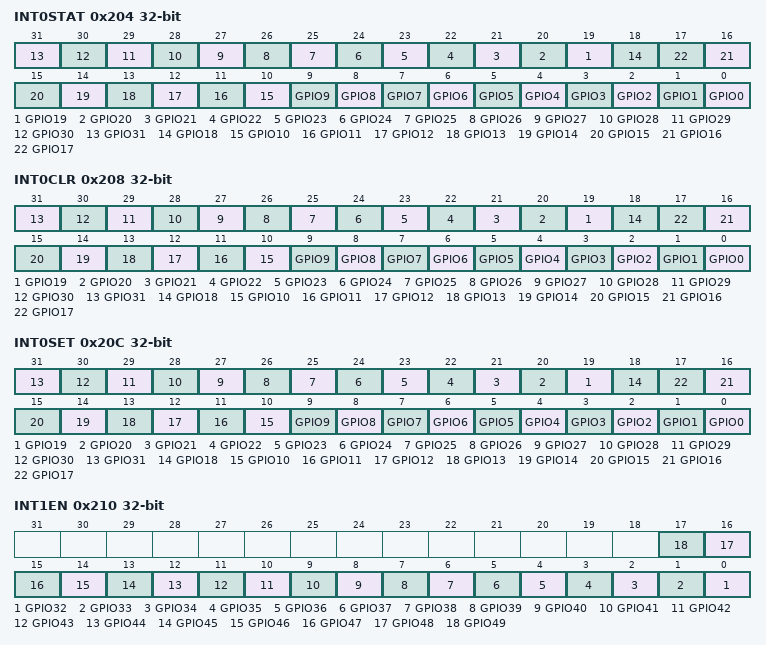
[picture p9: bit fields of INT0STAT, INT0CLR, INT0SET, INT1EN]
0x204 INT0STAT — GPIO Interrupt Registers 31-0: Status
  fields as INT0EN
0x208 INT0CLR — GPIO Interrupt Registers 31-0: Clear
  fields as INT0EN
0x20C INT0SET — GPIO Interrupt Registers 31-0: Set
  fields as INT0EN
0x210 INT1EN — GPIO Interrupt Registers 49-32: Enable
  [n-32] GPIO{n} (n=32..49) — GPIO{n} interrupt.
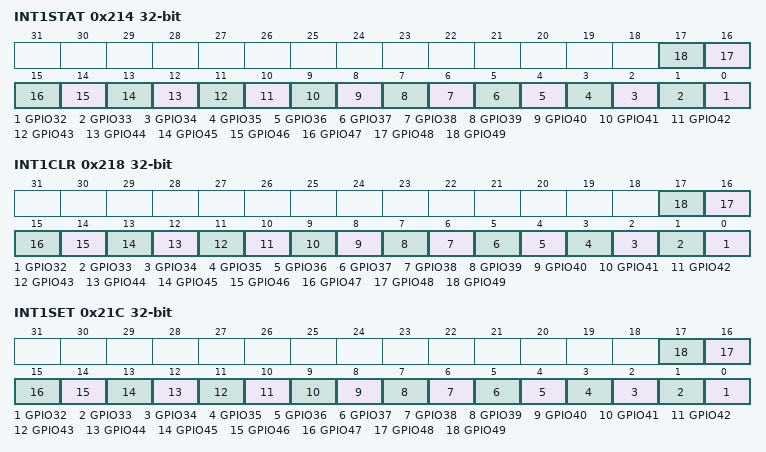
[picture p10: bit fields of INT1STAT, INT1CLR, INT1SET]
0x214 INT1STAT — GPIO Interrupt Registers 49-32: Status
  [n-32] GPIO{n} (n=32..49) — GPIO{n} interrupt.
0x218 INT1CLR — GPIO Interrupt Registers 49-32: Clear
  [n-32] GPIO{n} (n=32..49) — GPIO{n} interrupt.
0x21C INT1SET — GPIO Interrupt Registers 49-32: Set
  [n-32] GPIO{n} (n=32..49) — GPIO{n} interrupt.
